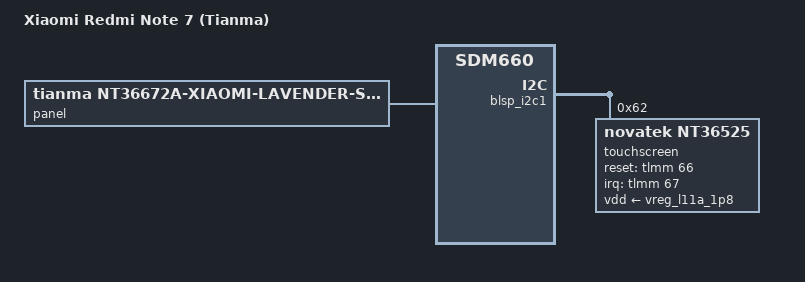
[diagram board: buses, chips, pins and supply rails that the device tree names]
// SPDX-License-Identifier: GPL-2.0-only
/*
 * Copyright (c) 2024, Barnabas Czeman <trabarni@gmail.com>
 */

/dts-v1/;

#include "sdm660-xiaomi-lavender-common.dtsi"

/ {
	model = "Xiaomi Redmi Note 7 (Tianma)";
	compatible = "xiaomi,lavender-tianma", "qcom,sdm660";
};

&blsp_i2c1 {
	status = "okay";

	/* Novatek NT36672A touchscreen */
	touchscreen@62 {
		compatible = "novatek,nt36525";
		reg = <0x62>;
		vdd-supply = <&vreg_l11a_1p8>;
		interrupt-parent = <&tlmm>;
		interrupts = <67 IRQ_TYPE_EDGE_RISING>;
		pinctrl-names = "default", "sleep";
		pinctrl-0 = <&ts_pins_active>;
		pinctrl-1 = <&ts_int_sleep &ts_rst_sleep>;
		reset-gpios = <&tlmm 66 GPIO_ACTIVE_HIGH>;
		touchscreen-size-x = <1080>;
		touchscreen-size-y = <2340>;
	};
};

&panel {
	compatible = "tianma,nt36672a-xiaomi-lavender-simple";
};

&tlmm {
	ts_pins_active: ts-pins-active-state {
		pins = "gpio66", "gpio67";
		function = "gpio";
		drive-strength = <16>;
		bias-pull-up;
	};

	ts_rst_sleep: ts-rst-sleep-state {
		pins = "gpio66";
		function = "gpio";
		drive-strength = <2>;
		bias-pull-down;
	};

	ts_int_sleep: ts-int-sleep-state {
		pins = "gpio67";
		function = "gpio";
		drive-strength = <2>;
		bias-disable;
	};
};
